# ballast register map
Vendor: tuni.fi; File version: 1.0
CPU: other r1p0, little endian, no MPU, no FPU, vendor SysTick, 3 interrupt priority bits
Registers are 32-bit, read-write, no defined reset value unless marked. A register's access mark holds for its fields unless they carry their own. Offsets are from the block's base; [hi:lo] are bit positions; lines under a group give offsets from that group; {n}, {i} and the like mark numbered series.

## HPC
Base 0x14000000
0x200000 CLINT group
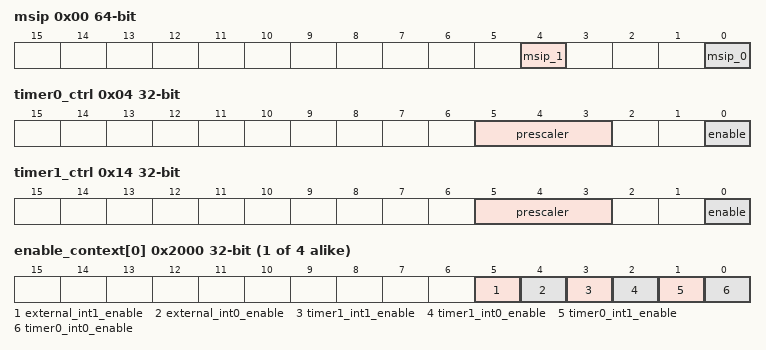
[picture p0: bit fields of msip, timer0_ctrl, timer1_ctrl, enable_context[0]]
  0x00 msip 64-bit — Machine mode software interrupt (IPI)
    [4] msip_1, [0] msip_0
  {0x4000+8j} mtimecmp[{j}] (j=0..1) 64-bit — Machine mode timer compare register for Hart 0
    [63:0] mtimecmp
  0xBFF8 mtime 64-bit — Timer register
0x210000 Timer group
  0x00 timer0_timer
  0x04 timer0_ctrl
    [5:3] prescaler, [0] enable
  0x08 timer0_cmp
  0x10 timer1_timer
  0x14 timer1_ctrl
    [5:3] prescaler, [0] enable
  0x18 timer1_cmp
0x220000 l2_config group
  0x00 l2_enable 64-bit access not given — Enable L2 cache
  0x08 core_enable 64-bit access not given — Enable shadow L1 caches in L2;NI
  0x10 l2_replacement_policy 64-bit access not given — Select L2 core priority algorithm; NI
  0x18 l2_arbitration_policy 64-bit access not given — Select L2 core priorities; NI
  0x20 l2_arbitration_priority 64-bit access not given — Select L2 replacement algorithm; NI
0x230000 cluster_config group
  0x00 core0_bootaddr 64-bit access not given — Core#0 boot address
  0x08 core1_bootaddr 64-bit access not given — Core#1 boot address
  0x10 core0_hart_id 64-bit access not given
  0x18 core1_hart_id 64-bit access not given
  0x20 rtc_cfg0 64-bit access not given — real time clock generator clock high count
  0x28 rtc_cfg1 64-bit access not given — real time clock generator clock low count
  0x30 rtc_cfg2 64-bit access not given — real time clock generator clock fine tune
  0x38 irq_status 64-bit access not given — interrupt flag statuses; NI
  0x40 force_irq 64-bit access not given — force interrupt line active; NI
  0x48 timer_base_addr 64-bit access not given — Timer base address
  0x50 timer_addr_length 64-bit access not given — Timer address space length
  0x58 plic_base_addr 64-bit access not given — PLIC base address
  0x60 plic_addr_length 64-bit access not given — PLIC address space length
  0x68 clint_base_addr 64-bit access not given — CLINT base address
  0x70 clint_addr_length 64-bit access not given — CLINT address space length
  0x78 rom_base_addr 64-bit access not given — Internal RAM base address
  0x80 rom_addr_length 64-bit access not given — Internal RAM address space length
  0x88 debug_base_addr 64-bit access not given — Debugger base address
  0x90 debug_addr_length 64-bit access not given — Debugger address space length
  0x98 l2cfg_base_addr 64-bit access not given — L2 cache config base address
  0xA0 l2cfg_addr_length 64-bit access not given — L2 cache config address space length
  0xA8 clustercfg_base_addr 64-bit access not given — Cluster config base address
  0xB0 clustercfg_addr_length 64-bit access not given — Cluster config address space length
  0xB8 dram_base_addr 64-bit access not given — External memory base address
  0xC0 dram_addr_length 64-bit access not given — External memory address space length
  0xC8 addr_valid_rule 64-bit access not given — Valid address space flags
  0xD0 nr_execute_region_rules 64-bit access not given — Number of execute regions
  0xD8 execute_region_addrbase0 64-bit access not given — Execution region base address
  0xE0 execute_region_length0 64-bit access not given — Execution region address space length
  {0xD8+0x10*j} execute_region_addr_base{j} 64-bit access not given (j=1..7)
  {0xE0+0x10*j} execute_region_length{j} 64-bit access not given (j=1..7)
  0x158 nr_cached_region_rules 64-bit access not given — Number of cached regions
  0x160 cached_region_addr_base0 64-bit access not given — Cached region base address
  {0x168+0x10*j} cached_region_length{j} 64-bit access not given (j=0..7)
  {0x160+0x10*j} cached_region_addr_base{j} 64-bit access not given (j=1..7)
  0x1E0 nr_nonidempotent_region_rules 64-bit access not given — Number of idempotent regions
  0x1E8 non_idempotent_region_addr_base0 64-bit access not given — Idempotent region base address
  0x1F0 non_idempotent_region_length0 64-bit access not given — Idempotent region address space length
  {0x1E8+0x10*j} non_idempotent_region_addr_base{j} 64-bit access not given (j=1..3)
  {0x1F0+0x10*j} non_idempotent_region_length{j} 64-bit access not given (j=1..3)
0x1000000 PLIC group
  {0x4+4j} timer_0_int_priority[{j}] (j=0..1)
    [31:0] timer_0_int_priority
  {0xC+4j} timer_1_int_priority[{j}] (j=0..1)
    [31:0] timer_1_int_priority
  {0x14+4j} external_0_int_priority[{j}] (j=0..1)
    [31:0] external_0_int_priority
  {0x2000+4j} enable_context[{j}] (j=0..3)
    [5] external_int1_enable, [4] external_int0_enable, [3] timer1_int1_enable, [2] timer1_int0_enable, [1] timer0_int1_enable, [0] timer0_int0_enable
  {0x200000+4j} priority_threshold_context[{j}] (j=0..3)
    [31:0] priority_threshold_context
  {0x200010+4j} claim_complete_context[{j}] (j=0..3) access not given
    [31:0] claim_complete_context
